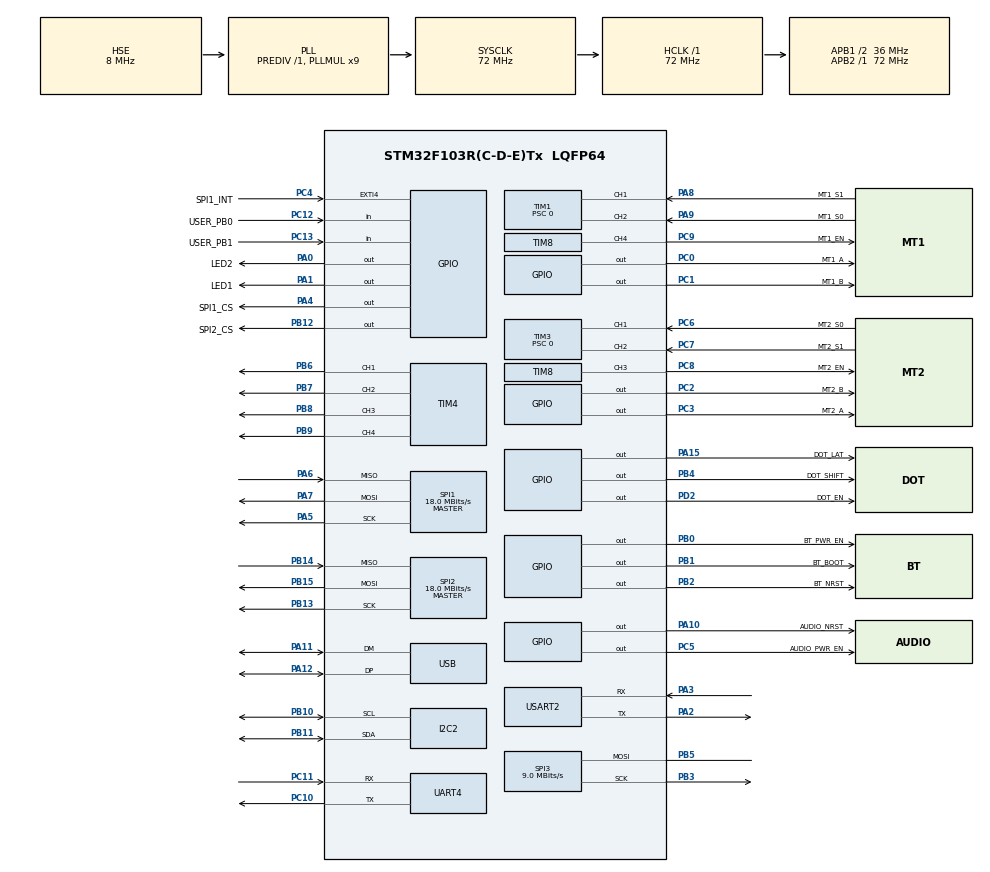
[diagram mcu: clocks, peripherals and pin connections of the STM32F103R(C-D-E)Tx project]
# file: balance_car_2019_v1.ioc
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Dma.Request0=USART2_RX
Dma.Request1=UART4_RX
Dma.UART4_RX.1.Direction=DMA_PERIPH_TO_MEMORY
Dma.UART4_RX.1.Instance=DMA2_Channel3
Dma.UART4_RX.1.MemDataAlignment=DMA_MDATAALIGN_BYTE
Dma.UART4_RX.1.MemInc=DMA_MINC_ENABLE
Dma.UART4_RX.1.Mode=DMA_NORMAL
Dma.UART4_RX.1.PeriphDataAlignment=DMA_PDATAALIGN_BYTE
Dma.UART4_RX.1.PeriphInc=DMA_PINC_DISABLE
Dma.UART4_RX.1.Priority=DMA_PRIORITY_LOW
Dma.USART2_RX.0.Direction=DMA_PERIPH_TO_MEMORY
Dma.USART2_RX.0.Instance=DMA1_Channel6
Dma.USART2_RX.0.MemDataAlignment=DMA_MDATAALIGN_BYTE
Dma.USART2_RX.0.MemInc=DMA_MINC_ENABLE
Dma.USART2_RX.0.Mode=DMA_NORMAL
Dma.USART2_RX.0.PeriphDataAlignment=DMA_PDATAALIGN_BYTE
Dma.USART2_RX.0.PeriphInc=DMA_PINC_DISABLE
Dma.USART2_RX.0.Priority=DMA_PRIORITY_LOW
Mcu.Family=STM32F1
Mcu.Name=STM32F103R(C-D-E)Tx
Mcu.Package=LQFP64
NVIC.DMA1_Channel6_IRQn=true\:5\:0\:true\:false\:true\:false\:true
NVIC.DMA2_Channel3_IRQn=true\:5\:0\:true\:false\:true\:false\:true
NVIC.EXTI4_IRQn=true\:7\:0\:true\:false\:true\:true\:true
NVIC.PriorityGroup=NVIC_PRIORITYGROUP_4
NVIC.TIM6_IRQn=true\:9\:0\:true\:false\:true\:true\:true
NVIC.TIM7_IRQn=true\:10\:0\:true\:false\:true\:true\:true
NVIC.UART4_IRQn=true\:6\:0\:true\:false\:true\:true\:true
NVIC.USART2_IRQn=true\:6\:0\:true\:false\:true\:true\:true
NVIC.USB_HP_CAN1_TX_IRQn=true\:4\:0\:true\:false\:true\:true\:true
NVIC.USB_LP_CAN1_RX0_IRQn=true\:6\:0\:true\:false\:true\:false\:true
PA0-WKUP.GPIO_Label=LED2
PA0-WKUP.Signal=GPIO_Output
PA1.GPIO_Label=LED1
PA1.Signal=GPIO_Output
PA10.GPIO_Label=AUDIO_NRST
PA10.Signal=GPIO_Output
PA11.Mode=Device
PA11.Signal=USB_DM
PA12.Mode=Device
PA12.Signal=USB_DP
PA13.Mode=Serial_Wire
PA13.Signal=SYS_JTMS-SWDIO
PA14.Mode=Serial_Wire
PA14.Signal=SYS_JTCK-SWCLK
PA15.GPIO_Label=DOT_LAT
PA15.Signal=GPIO_Output
PA2.Mode=Asynchronous
PA2.Signal=USART2_TX
PA3.Mode=Asynchronous
PA3.Signal=USART2_RX
PA4.GPIO_Label=SPI1_CS
PA4.GPIO_PuPd=GPIO_PULLUP
PA4.PinState=GPIO_PIN_SET
PA4.Signal=GPIO_Output
PA5.Mode=Full_Duplex_Master
PA5.Signal=SPI1_SCK
PA6.Mode=Full_Duplex_Master
PA6.Signal=SPI1_MISO
PA7.Mode=Full_Duplex_Master
PA7.Signal=SPI1_MOSI
PA8.GPIO_Label=MT1_S1
PA8.Signal=S_TIM1_CH1
PA9.GPIO_Label=MT1_S0
PA9.Signal=S_TIM1_CH2
PB0.GPIO_Label=BT_PWR_EN
PB0.PinState=GPIO_PIN_RESET
PB0.Signal=GPIO_Output
PB1.GPIO_Label=BT_BOOT
PB1.Signal=GPIO_Output
PB10.Mode=I2C
PB10.Signal=I2C2_SCL
PB11.Mode=I2C
PB11.Signal=I2C2_SDA
PB12.GPIO_Label=SPI2_CS
PB12.Signal=GPIO_Output
PB13.Mode=Full_Duplex_Master
PB13.Signal=SPI2_SCK
PB14.Mode=Full_Duplex_Master
PB14.Signal=SPI2_MISO
PB15.Mode=Full_Duplex_Master
PB15.Signal=SPI2_MOSI
PB2.GPIO_Label=BT_NRST
PB2.GPIO_ModeDefaultOutputPP=GPIO_MODE_OUTPUT_PP
PB2.PinState=GPIO_PIN_SET
PB2.Signal=GPIO_Output
PB3.Mode=Simplex_Bidirectional_Master
PB3.Signal=SPI3_SCK
PB4.GPIO_Label=DOT_SHIFT
PB4.Signal=GPIO_Output
PB5.Mode=Simplex_Bidirectional_Master
PB5.Signal=SPI3_MOSI
PB6.Signal=S_TIM4_CH1
PB7.Signal=S_TIM4_CH2
PB8.Signal=S_TIM4_CH3
PB9.Signal=S_TIM4_CH4
PC0.GPIO_Label=MT1_A
PC0.Signal=GPIO_Output
PC1.GPIO_Label=MT1_B
PC1.Signal=GPIO_Output
PC10.Mode=Asynchronous
PC10.Signal=UART4_TX
PC11.Mode=Asynchronous
PC11.Signal=UART4_RX
PC12.GPIO_Label=USER_PB0
PC12.Signal=GPIO_Input
PC13-TAMPER-RTC.GPIO_Label=USER_PB1
PC13-TAMPER-RTC.Signal=GPIO_Input
PC14-OSC32_IN.Mode=LSE-External-Oscillator
PC14-OSC32_IN.Signal=RCC_OSC32_IN
PC15-OSC32_OUT.Mode=LSE-External-Oscillator
PC15-OSC32_OUT.Signal=RCC_OSC32_OUT
PC2.GPIO_Label=MT2_B
PC2.Signal=GPIO_Output
PC3.GPIO_Label=MT2_A
PC3.Signal=GPIO_Output
PC4.GPIO_Label=SPI1_INT
PC4.GPIO_ModeDefaultEXTI=GPIO_MODE_IT_FALLING
PC4.GPIO_PuPd=GPIO_PULLUP
PC4.Signal=GPXTI4
PC5.GPIO_Label=AUDIO_PWR_EN
PC5.Signal=GPIO_Output
PC6.GPIO_Label=MT2_S0
PC6.Signal=S_TIM3_CH1
PC7.GPIO_Label=MT2_S1
PC7.Signal=S_TIM3_CH2
PC8.GPIO_Label=MT2_EN
PC8.Signal=S_TIM8_CH3
PC9.GPIO_Label=MT1_EN
PC9.Signal=S_TIM8_CH4
PD0-OSC_IN.Mode=HSE-External-Oscillator
PD0-OSC_IN.Signal=RCC_OSC_IN
PD1-OSC_OUT.Mode=HSE-External-Oscillator
PD1-OSC_OUT.Signal=RCC_OSC_OUT
PD2.GPIO_Label=DOT_EN
PD2.Signal=GPIO_Output
ProjectManager.HeapSize=0x1000
ProjectManager.StackSize=0x1000
ProjectManager.TargetToolchain=MDK-ARM V5
RCC.ADCPresc=RCC_ADCPCLK2_DIV6
RCC.AHBFreq_Value=72000000
RCC.APB1CLKDivider=RCC_HCLK_DIV2
RCC.APB1Freq_Value=36000000
RCC.APB1TimFreq_Value=72000000
RCC.APB2Freq_Value=72000000
RCC.APB2TimFreq_Value=72000000
RCC.HCLKFreq_Value=72000000
RCC.PLLMUL=RCC_PLL_MUL9
RCC.PLLSourceVirtual=RCC_PLLSOURCE_HSE
RCC.SYSCLKFreq_VALUE=72000000
RCC.SYSCLKSource=RCC_SYSCLKSOURCE_PLLCLK
RCC.USBFreq_Value=48000000
RCC.USBPrescaler=RCC_USBCLKSOURCE_PLL_DIV1_5
SH.S_TIM1_CH1.0=TIM1_CH1,Encoder_Interface
SH.S_TIM1_CH2.0=TIM1_CH2,Encoder_Interface
SH.S_TIM3_CH1.0=TIM3_CH1,Encoder_Interface
SH.S_TIM3_CH2.0=TIM3_CH2,Encoder_Interface
SH.S_TIM4_CH1.0=TIM4_CH1,PWM Generation1 CH1
SH.S_TIM4_CH2.0=TIM4_CH2,PWM Generation2 CH2
SH.S_TIM4_CH3.0=TIM4_CH3,PWM Generation3 CH3
SH.S_TIM4_CH4.0=TIM4_CH4,PWM Generation4 CH4
SH.S_TIM8_CH3.0=TIM8_CH3,PWM Generation3 CH3
SH.S_TIM8_CH4.0=TIM8_CH4,PWM Generation4 CH4
SPI1.BaudRatePrescaler=SPI_BAUDRATEPRESCALER_4
SPI1.CLKPhase=SPI_PHASE_2EDGE
SPI1.CLKPolarity=SPI_POLARITY_LOW
SPI1.CRCCalculation=SPI_CRCCALCULATION_DISABLE
SPI1.CalculateBaudRate=18.0 MBits/s
SPI1.Direction=SPI_DIRECTION_2LINES
SPI1.Mode=SPI_MODE_MASTER
SPI1.VirtualType=VM_MASTER
SPI2.CLKPhase=SPI_PHASE_2EDGE
SPI2.CLKPolarity=SPI_POLARITY_HIGH
SPI2.CalculateBaudRate=18.0 MBits/s
SPI2.Direction=SPI_DIRECTION_2LINES
SPI2.Mode=SPI_MODE_MASTER
SPI2.VirtualType=VM_MASTER
SPI3.BaudRatePrescaler=SPI_BAUDRATEPRESCALER_4
SPI3.CLKPhase=SPI_PHASE_2EDGE
SPI3.CLKPolarity=SPI_POLARITY_HIGH
SPI3.CalculateBaudRate=9.0 MBits/s
SPI3.Direction=SPI_DIRECTION_1LINE
SPI3.Mode=SPI_MODE_MASTER
SPI3.VirtualType=VM_MASTER
TIM1.EncoderMode=TIM_ENCODERMODE_TI12
TIM1.IC1Filter=0
TIM1.IC2Filter=0
TIM1.Period=65535
TIM1.Prescaler=0
TIM3.EncoderMode=TIM_ENCODERMODE_TI12
TIM3.IC1Filter=0
TIM3.IC2Filter=0
TIM3.Period=65535
TIM3.Prescaler=0
TIM4.Channel-PWM\ Generation1\ CH1=TIM_CHANNEL_1
TIM4.Channel-PWM\ Generation2\ CH2=TIM_CHANNEL_2
TIM4.Channel-PWM\ Generation3\ CH3=TIM_CHANNEL_3
TIM4.Channel-PWM\ Generation4\ CH4=TIM_CHANNEL_4
TIM6.Period=49
TIM6.Prescaler=7199
TIM7.AutoReloadPreload=TIM_AUTORELOAD_PRELOAD_ENABLE
TIM7.Period=9999
TIM7.Prescaler=7199
TIM8.AutoReloadPreload=TIM_AUTORELOAD_PRELOAD_ENABLE
TIM8.Channel-PWM\ Generation3\ CH3=TIM_CHANNEL_3
TIM8.Channel-PWM\ Generation4\ CH4=TIM_CHANNEL_4
TIM8.Period=999
TIM8.Prescaler=5
UART4.VirtualMode=Asynchronous
USART2.VirtualMode=VM_ASYNC
USB_DEVICE.CLASS_NAME_FS=CDC
USB_DEVICE.VirtualMode=Cdc
USB_DEVICE.VirtualModeFS=Cdc_FS
VP_TIM6_VS_ClockSourceINT.Mode=Enable_Timer
VP_TIM7_VS_ClockSourceINT.Mode=Enable_Timer
VP_USB_DEVICE_VS_USB_DEVICE_CDC_FS.Mode=CDC_FS
board=balance_car_2019_v1

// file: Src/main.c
/* USER CODE BEGIN Header */
/**
  ******************************************************************************
  * @file           : main.c
  * @brief          : Main program body
  ******************************************************************************
  * This notice applies to any and all portions of this file
  * that are not between comment pairs USER CODE BEGIN and
  * USER CODE END. Other portions of this file, whether
  * inserted by the user or by software development tools
  * are owned by their respective copyright owners.
  *
  * Copyright (c) 2019 STMicroelectronics International N.V.
  * All rights reserved.
  *
  * Redistribution and use in source and binary forms, with or without
  * modification, are permitted, provided that the following conditions are met:
  *
  * 1. Redistribution of source code must retain the above copyright notice,
  *    this list of conditions and the following disclaimer.
  * 2. Redistributions in binary form must reproduce the above copyright notice,
  *    this list of conditions and the following disclaimer in the documentation
  *    and/or other materials provided with the distribution.
  * 3. Neither the name of STMicroelectronics nor the names of other
  *    contributors to this software may be used to endorse or promote products
  *    derived from this software without specific written permission.
  * 4. This software, including modifications and/or derivative works of this
  *    software, must execute solely and exclusively on microcontroller or
  *    microprocessor devices manufactured by or for STMicroelectronics.
  * 5. Redistribution and use of this software other than as permitted under
  *    this license is void and will automatically terminate your rights under
  *    this license.
  *
  * THIS SOFTWARE IS PROVIDED BY STMICROELECTRONICS AND CONTRIBUTORS "AS IS"
  * AND ANY EXPRESS, IMPLIED OR STATUTORY WARRANTIES, INCLUDING, BUT NOT
  * LIMITED TO, THE IMPLIED WARRANTIES OF MERCHANTABILITY, FITNESS FOR A
  * PARTICULAR PURPOSE AND NON-INFRINGEMENT OF THIRD PARTY INTELLECTUAL PROPERTY
  * RIGHTS ARE DISCLAIMED TO THE FULLEST EXTENT PERMITTED BY LAW. IN NO EVENT
  * SHALL STMICROELECTRONICS OR CONTRIBUTORS BE LIABLE FOR ANY DIRECT, INDIRECT,
  * INCIDENTAL, SPECIAL, EXEMPLARY, OR CONSEQUENTIAL DAMAGES (INCLUDING, BUT NOT
  * LIMITED TO, PROCUREMENT OF SUBSTITUTE GOODS OR SERVICES; LOSS OF USE, DATA,
  * OR PROFITS; OR BUSINESS INTERRUPTION) HOWEVER CAUSED AND ON ANY THEORY OF
  * LIABILITY, WHETHER IN CONTRACT, STRICT LIABILITY, OR TORT (INCLUDING
  * NEGLIGENCE OR OTHERWISE) ARISING IN ANY WAY OUT OF THE USE OF THIS SOFTWARE,
  * EVEN IF ADVISED OF THE POSSIBILITY OF SUCH DAMAGE.
  *
  ******************************************************************************
  */
/* USER CODE END Header */

#include "main.h"
#include "dma.h"
#include "i2c.h"
#include "spi.h"
#include "tim.h"
#include "usart.h"
#include "usb_device.h"
#include "gpio.h"

/* USER CODE BEGIN Includes */
#include "mpu9250.h"
#include "balance_car.h"
#include "uart_dma.h"
#include "bt_uart.h"
#include "ld3320.h"
#include "moto_ctrl.h"
/* USER CODE END Includes */

void SystemClock_Config(void);

int main(void)
{

  /* MCU Configuration--------------------------------------------------------*/

  /* Reset of all peripherals, Initializes the Flash interface and the Systick. */
  HAL_Init();

  /* Configure the system clock */
  SystemClock_Config();

  /* Initialize all configured peripherals */
  MX_GPIO_Init();
  MX_DMA_Init();
  MX_SPI1_Init();
  MX_SPI3_Init();
  MX_TIM3_Init();
  MX_TIM6_Init();
  MX_TIM8_Init();
  MX_USB_DEVICE_Init();
  MX_USART2_UART_Init();
  MX_UART4_Init();
  MX_I2C2_Init();
  MX_SPI2_Init();
  MX_TIM1_Init();
  MX_TIM7_Init();
  MX_TIM4_Init();
  /* USER CODE BEGIN 2 */
	StartAllUartDMAReceive();
	MPU9250_Init();
	SetWorkMode( g_SysMode );
//	StartMeasureSpeed();
	EnableBT();
	HAL_Delay(1000);
	HAL_UART_Transmit(&huart2,"@NAME|20408&",strlen("@NAME|20408&"),HAL_MAX_DELAY);

/*
	LD3320_Power(1);
	HAL_Delay(100);
	RunASR();
*/
  /* USER CODE END 2 */

  /* Infinite loop */
  /* USER CODE BEGIN WHILE */
  while (1)
  {
			UserTask();

    /* USER CODE END WHILE */

    /* USER CODE BEGIN 3 */
		/* printf("LeftSpeed = %d , Distance = %d ; RightSpeed = %d , Distance = %d \n",
			 SpeedData.LeftSpeed , SpeedData.LeftDistance , SpeedData.RightSpeed , SpeedData.RightDistance);
		   HAL_Delay(1000);
		*/
  }
  /* USER CODE END 3 */
}

void SystemClock_Config(void)
{
  RCC_OscInitTypeDef RCC_OscInitStruct = {0};
  RCC_ClkInitTypeDef RCC_ClkInitStruct = {0};
  RCC_PeriphCLKInitTypeDef PeriphClkInit = {0};

  /** Initializes the CPU, AHB and APB busses clocks
  */
  RCC_OscInitStruct.OscillatorType = RCC_OSCILLATORTYPE_HSE;
  RCC_OscInitStruct.HSEState = RCC_HSE_ON;
  RCC_OscInitStruct.HSEPredivValue = RCC_HSE_PREDIV_DIV1;
  RCC_OscInitStruct.HSIState = RCC_HSI_ON;
  RCC_OscInitStruct.PLL.PLLState = RCC_PLL_ON;
  RCC_OscInitStruct.PLL.PLLSource = RCC_PLLSOURCE_HSE;
  RCC_OscInitStruct.PLL.PLLMUL = RCC_PLL_MUL9;
  if (HAL_RCC_OscConfig(&RCC_OscInitStruct) != HAL_OK)
  {
    Error_Handler();
  }
  /** Initializes the CPU, AHB and APB busses clocks
  */
  RCC_ClkInitStruct.ClockType = RCC_CLOCKTYPE_HCLK|RCC_CLOCKTYPE_SYSCLK
                              |RCC_CLOCKTYPE_PCLK1|RCC_CLOCKTYPE_PCLK2;
  RCC_ClkInitStruct.SYSCLKSource = RCC_SYSCLKSOURCE_PLLCLK;
  RCC_ClkInitStruct.AHBCLKDivider = RCC_SYSCLK_DIV1;
  RCC_ClkInitStruct.APB1CLKDivider = RCC_HCLK_DIV2;
  RCC_ClkInitStruct.APB2CLKDivider = RCC_HCLK_DIV1;

  if (HAL_RCC_ClockConfig(&RCC_ClkInitStruct, FLASH_LATENCY_2) != HAL_OK)
  {
    Error_Handler();
  }
  PeriphClkInit.PeriphClockSelection = RCC_PERIPHCLK_USB;
  PeriphClkInit.UsbClockSelection = RCC_USBCLKSOURCE_PLL_DIV1_5;
  if (HAL_RCCEx_PeriphCLKConfig(&PeriphClkInit) != HAL_OK)
  {
    Error_Handler();
  }
}

void Error_Handler(void)
{
}

/************************ (C) COPYRIGHT STMicroelectronics *****END OF FILE****/
